# mcr_me15 register map
Registers are access not given, no defined reset value unless marked. A register's access mark holds for its fields unless they carry their own. Offsets are from the block's base; lines under a group give offsets from that group; [hi:lo] are bit positions; {n}, {i} and the like mark numbered series; 'fields as' and 'values as' point back to an identical list; <NAME> marks a mode.

## Memory map
0x40106000 MCR size 0x400 — Miscellaneous Control Registers.

## MCR — Miscellaneous Control Registers.
Base 0x40106000
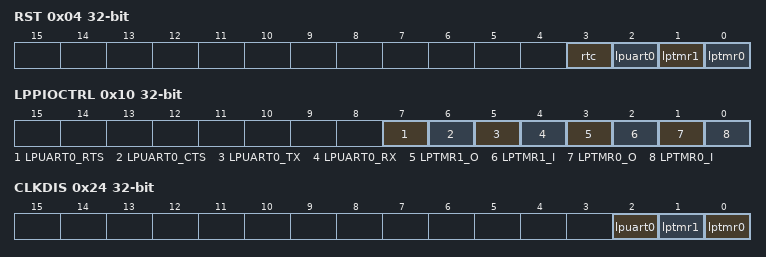
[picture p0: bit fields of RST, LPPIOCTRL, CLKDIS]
0x04 RST — Reset control register 0.
  [3] rtc — Setting this bit will reset the Real-Time Clock.
    1=rst (Reset Real-Time Clock.)
  [2] lpuart0 — Setting this bit will reset LPUART0.
    1=rst (Reset LPUART0.)
  [1] lptmr1 — Setting this bit will reset LPTMR1.
    1=rst (Reset LPTMR1.)
  [0] lptmr0 — Setting this bit will reset LPTMR0.
    1=rst (Reset LPTMR0.)
0x10 LPPIOCTRL — Low-power peripheral IO control.
  [7] LPUART0_RTS — Setting this bit will enable the low-power UART 0 (UART3) RTS pin while operating in low-power modes.
    0=dis (Disable LPUART0 RTS pin.); 1=en (Enable LPUART0 RTS pin.)
  [6] LPUART0_CTS — Setting this bit will enable the low-power UART 0 (UART3) CTS pin while operating in low-power modes.
    0=dis (Disable LPUART0 CTS pin.); 1=en (Enable LPUART0 CTS pin.)
  [5] LPUART0_TX — Setting this bit will enable the low-power UART 0 (UART3) TX pin while operating in low-power modes.
    0=dis (Disable LPUART0 TX pin.); 1=en (Enable LPUART0 TX pin.)
  [4] LPUART0_RX — Setting this bit will enable the low-power UART 0 (UART3) RX pin while operating in low-power modes.
    0=dis (Disable LPUART0 RX pin.); 1=en (Enable LPUART0 RX pin.)
  [3] LPTMR1_O — Setting this bit will enable the low-power timer 1 (timer 5) output pin while operating in low-power modes.
    0=dis (Disable LPTMR1 output pin.); 1=en (Enable LPTMR1 output pin.)
  [2] LPTMR1_I — Setting this bit will enable the low-power timer 1 (timer 5) input pin while operating in low-power modes.
    0=dis (Disable LPTMR1 input pin.); 1=en (Enable LPTMR1 input pin.)
  [1] LPTMR0_O — Setting this bit will enable the low-power timer 0 (timer 4) output pin while operating in low-power modes.
    0=dis (Disable LPTMR0 output pin.); 1=en (Enable LPTMR0 output pin.)
  [0] LPTMR0_I — Setting this bit will enable the low-power timer 0 (timer 4) input pin while operating in low-power modes.
    0=dis (Disable LPTMR0 input pin.); 1=en (Enable LPTMR0 input pin.)
0x24 CLKDIS — Peripheral clock control register.
  [2] lpuart0 — Clearing this bit will enable the low-power UART 0 (UART3) peripheral clock.
    0=en (Enable LPUART0 clock.); 1=dis (Disable LPUART0 clock.)
  [1] lptmr1 — Clearing this bit will enable the low-power timer 1 (timer 5) peripheral clock.
    0=en (Enable LPTMR1 clock.); 1=dis (Disable LPTMR1 clock.)
  [0] lptmr0 — Clearing this bit will enable the low-power timer 0 (timer 4) peripheral clock.
    0=en (Enable LPTMR0 clock.); 1=dis (Disable LPTMR0 clock.)
